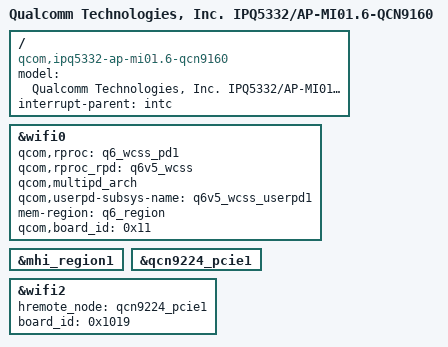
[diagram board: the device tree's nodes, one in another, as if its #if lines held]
// SPDX-License-Identifier: (GPL-2.0+ OR BSD-3-Clause)
/*
 * IPQ5332 AP-MI01.6-QCN9160 board device tree source
 *
 * Copyright (c) 2020-2021 The Linux Foundation. All rights reserved.
 * Copyright (c) 2022-2023  Qualcomm Innovation Center, Inc. All rights reserved.
 */

/dts-v1/;

#include "ipq5332-mi01.6.dtsi"

#ifdef __IPQ_MEM_PROFILE_512_MB__
#include "ipq5332-512MB-memory.dtsi"
#else
#include "ipq5332-default-memory.dtsi"
#endif

/ {
	#address-cells = <0x2>;
	#size-cells = <0x2>;
	model = "Qualcomm Technologies, Inc. IPQ5332/AP-MI01.6-QCN9160";
	compatible = "qcom,ipq5332-ap-mi01.6-qcn9160", "qcom,ipq5332";
	interrupt-parent = <&intc>;
};

&wifi0 {
	qcom,rproc = <&q6_wcss_pd1>;
	qcom,rproc_rpd = <&q6v5_wcss>;
	qcom,multipd_arch;
	qcom,userpd-subsys-name = "q6v5_wcss_userpd1";
#if defined(__CNSS2__)
	mem-region = <&q6_region>;
#else
	memory-region = <&q6_region>;
	qcom,wsi = <&wsi>;
#endif
	qcom,board_id = <0x11>;
	status = "ok";
};

&mhi_region1 {
	status = "ok";
};

&qcn9224_pcie1 {
	status = "ok";
};

/* QCN9224 5G+6G */
&wifi2 {
	hremote_node = <&qcn9224_pcie1>;
	board_id = <0x1019>;
	status = "ok";
};
